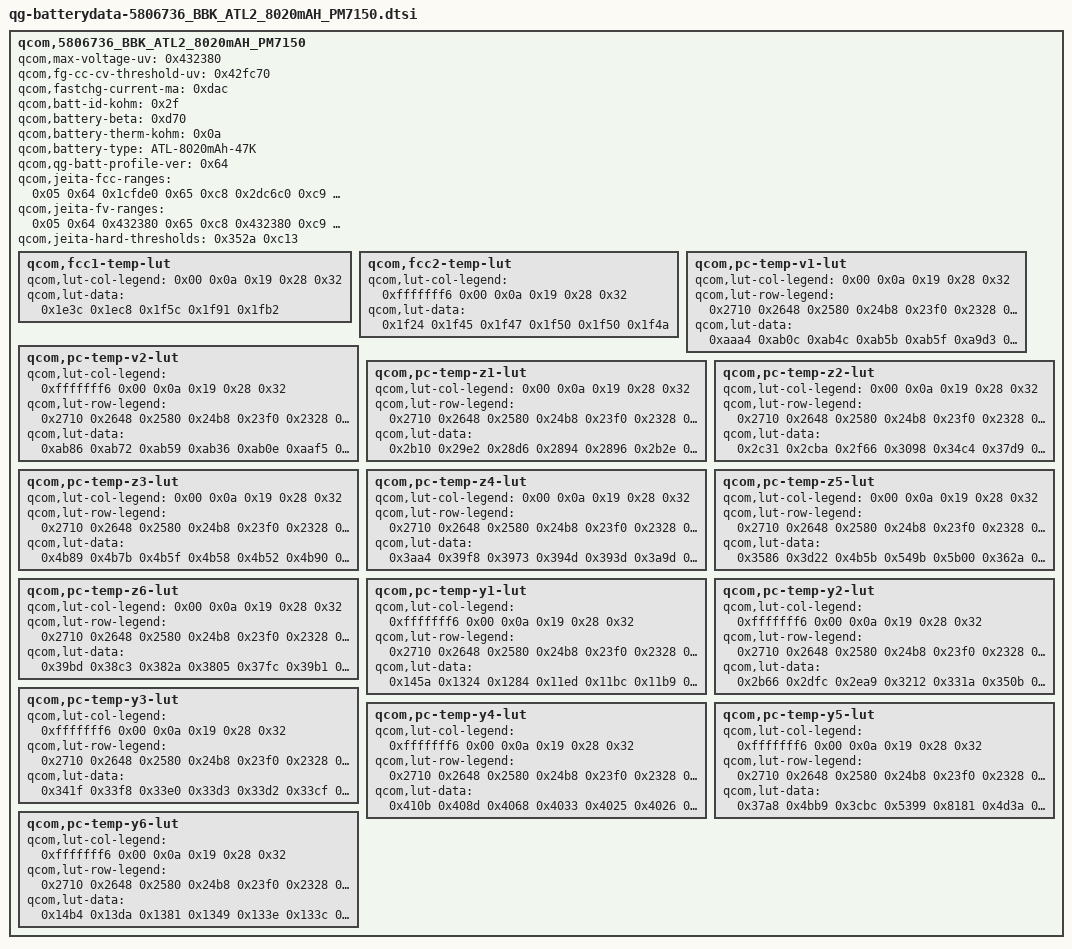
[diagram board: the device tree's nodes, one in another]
 /*
 * Copyright (c) 2026 XiKoTaSu <3329989998@qq.com>
 */


		qcom,5806736_BBK_ATL2_8020mAH_PM7150 {
				qcom,max-voltage-uv = <0x432380>;
				qcom,fg-cc-cv-threshold-uv = <0x42fc70>;
				qcom,fastchg-current-ma = <0xdac>;
				qcom,batt-id-kohm = <0x2f>;
				qcom,battery-beta = <0xd70>;
				qcom,battery-therm-kohm = <0x0a>;
				qcom,battery-type = "ATL-8020mAh-47K";
				qcom,qg-batt-profile-ver = <0x64>;
				qcom,jeita-fcc-ranges = <0x05 0x64 0x1cfde0 0x65 0xc8 0x2dc6c0 0xc9 0x1c2 0x3567e0 0x1c3 0x221 0x2625a0>;
				qcom,jeita-fv-ranges = <0x05 0x64 0x432380 0x65 0xc8 0x432380 0xc9 0x1c2 0x432380 0x1c3 0x221 0x3e8fa0>;
				qcom,jeita-hard-thresholds = <0x352a 0xc13>;

				qcom,fcc1-temp-lut {
					qcom,lut-col-legend = <0x00 0x0a 0x19 0x28 0x32>;
					qcom,lut-data = <0x1e3c 0x1ec8 0x1f5c 0x1f91 0x1fb2>;
				};

				qcom,fcc2-temp-lut {
					qcom,lut-col-legend = <0xfffffff6 0x00 0x0a 0x19 0x28 0x32>;
					qcom,lut-data = <0x1f24 0x1f45 0x1f47 0x1f50 0x1f50 0x1f4a>;
				};

				qcom,pc-temp-v1-lut {
					qcom,lut-col-legend = <0x00 0x0a 0x19 0x28 0x32>;
					qcom,lut-row-legend = <0x2710 0x2648 0x2580 0x24b8 0x23f0 0x2328 0x2260 0x2198 0x20d0 0x2008 0x1f40 0x1e78 0x1db0 0x1ce8 0x1c20 0x1b58 0x1a90 0x19c8 0x1900 0x1838 0x1770 0x16a8 0x15e0 0x1518 0x1450 0x1388 0x12c0 0x11f8 0x1130 0x1068 0xfa0 0xed8 0xe10 0xd48 0xc80 0xbb8 0xaf0 0xa28 0x960 0x898 0x7d0 0x708 0x640 0x578 0x4b0 0x3e8 0x384 0x320 0x2bc 0x258 0x1f4 0x190 0x12c 0xc8 0x64 0x00>;
					qcom,lut-data = <0xaaa4 0xab0c 0xab4c 0xab5b 0xab5f 0xa9d3 0xaa2c 0xaa8f 0xaa9c 0xaaa7 0xa8d4 0xa942 0xa9af 0xa9c9 0xa9d7 0xa7c5 0xa84c 0xa8c6 0xa8e9 0xa8fa 0xa6cb 0xa753 0xa7cf 0xa7fa 0xa810 0xa5dc 0xa660 0xa6d6 0xa702 0xa71b 0xa4f8 0xa572 0xa5e3 0xa60e 0xa62a 0xa422 0xa488 0xa4f4 0xa51c 0xa53b 0xa353 0xa3a6 0xa408 0xa42e 0xa44e 0xa283 0xa2c9 0xa31e 0xa345 0xa363 0xa1b0 0xa1f1 0xa239 0xa260 0xa27b 0xa0e4 0xa11d 0xa15b 0xa17e 0xa199 0xa02c 0xa051 0xa082 0xa09f 0xa0ba 0x9f7e 0x9f96 0x9fb2 0x9fc8 0x9fe2 0x9eb0 0x9ed8 0x9eeb 0x9ef8 0x9f0e 0x9d9e 0x9df7 0x9e24 0x9e2f 0x9e40 0x9c91 0x9cf0 0x9d53 0x9d6b 0x9d7c 0x9be0 0x9c11 0x9c82 0x9cae 0x9cc1 0x9b61 0x9b7b 0x9bbe 0x9bef 0x9c03 0x9acf 0x9af4 0x9b09 0x9b2e 0x9b41 0x99ef 0x9a3b 0x9a4e 0x9a69 0x9a7a 0x98fe 0x993a 0x996f 0x998e 0x99a3 0x985f 0x9865 0x988a 0x98a5 0x98bc 0x97ef 0x97eb 0x97e1 0x97ec 0x97fd 0x9795 0x978b 0x9761 0x9761 0x976e 0x974e 0x972e 0x96f1 0x96e9 0x96f3 0x9713 0x96d2 0x9689 0x967a 0x967f 0x96d3 0x967c 0x962a 0x9616 0x9613 0x968a 0x962a 0x95d4 0x95ba 0x95b2 0x9644 0x95de 0x9587 0x9564 0x9557 0x9608 0x959d 0x9543 0x9518 0x9506 0x95d2 0x9566 0x9508 0x94d5 0x94be 0x95a0 0x9534 0x94d4 0x949b 0x947e 0x9572 0x9509 0x94a6 0x9464 0x9442 0x9547 0x94e3 0x947f 0x9433 0x940c 0x951d 0x94bb 0x9458 0x9401 0x93d5 0x94f8 0x9495 0x942e 0x93cd 0x9398 0x94ca 0x946a 0x9402 0x9395 0x9355 0x947d 0x9423 0x93c0 0x9350 0x9308 0x9411 0x93bb 0x935e 0x92f7 0x92ae 0x939b 0x9347 0x92ee 0x9290 0x9248 0x9313 0x92c7 0x9275 0x9216 0x91ce 0x9283 0x923b 0x91ef 0x918e 0x9147 0x91ea 0x919c 0x9155 0x90fe 0x90ba 0x917e 0x9135 0x90e7 0x9092 0x9052 0x9148 0x90fa 0x90ae 0x9059 0x901f 0x912c 0x90e4 0x909c 0x9049 0x900e 0x9103 0x90cf 0x908c 0x903b 0x8ffd 0x909d 0x9089 0x9062 0x9010 0x8fcb 0x8f69 0x8f97 0x8fa4 0x8f43 0x8ee1 0x8d3b 0x8d9e 0x8df3 0x8da8 0x8d43 0x8a60 0x8aea 0x8b8c 0x8b6b 0x8b09 0x870a 0x878c 0x8863 0x8869 0x880c 0x82f7 0x8369 0x8452 0x8465 0x8405 0x7d5b 0x7dba 0x7ead 0x7eb5 0x7e42 0x7530 0x7530 0x7530 0x7530 0x7530>;
				};

				qcom,pc-temp-v2-lut {
					qcom,lut-col-legend = <0xfffffff6 0x00 0x0a 0x19 0x28 0x32>;
					qcom,lut-row-legend = <0x2710 0x2648 0x2580 0x24b8 0x23f0 0x2328 0x2260 0x2198 0x20d0 0x2008 0x1f40 0x1e78 0x1db0 0x1ce8 0x1c20 0x1b58 0x1a90 0x19c8 0x1900 0x1838 0x1770 0x16a8 0x15e0 0x1518 0x1450 0x1388 0x12c0 0x11f8 0x1130 0x1068 0xfa0 0xed8 0xe10 0xd48 0xc80 0xbb8 0xaf0 0xa28 0x960 0x898 0x7d0 0x708 0x640 0x578 0x4b0 0x3e8 0x384 0x320 0x2bc 0x258 0x1f4 0x190 0x12c 0xc8 0x64 0x00>;
					qcom,lut-data = <0xab86 0xab72 0xab59 0xab36 0xab0e 0xaaf5 0xaa28 0xaa49 0xaa54 0xaa3f 0xaa1f 0xaa08 0xa8e2 0xa92c 0xa951 0xa947 0xa92e 0xa91a 0xa7b9 0xa81b 0xa851 0xa84e 0xa83b 0xa829 0xa6a9 0xa716 0xa754 0xa753 0xa743 0xa734 0xa5a8 0xa61a 0xa65b 0xa65a 0xa64c 0xa640 0xa4b0 0xa523 0xa565 0xa566 0xa55a 0xa54e 0xa3c3 0xa433 0xa474 0xa475 0xa46a 0xa45f 0xa2d7 0xa34b 0xa38a 0xa389 0xa37f 0xa374 0xa1e9 0xa26a 0xa2a6 0xa2a0 0xa297 0xa28d 0xa110 0xa191 0xa1c6 0xa1bc 0xa1b3 0xa1aa 0xa063 0xa0c7 0xa0ea 0xa0dc 0xa0d4 0xa0cb 0x9fc4 0xa002 0xa012 0xa000 0x9ff8 0x9fef 0x9ef1 0x9f2b 0x9f3e 0x9f2d 0x9f23 0x9f1c 0x9dcf 0x9e42 0x9e6f 0x9e62 0x9e54 0x9e4d 0x9ca5 0x9d52 0x9d99 0x9d99 0x9d8c 0x9d85 0x9b99 0x9c5c 0x9caf 0x9ccc 0x9cce 0x9cc7 0x9a9d 0x9b65 0x9bbe 0x9c00 0x9c14 0x9c0d 0x99bf 0x9a80 0x9adc 0x9b36 0x9b50 0x9b4a 0x98fb 0x99a9 0x9a05 0x9a6c 0x9a82 0x9a7b 0x9846 0x98e0 0x9938 0x999e 0x99ae 0x99a8 0x979a 0x9822 0x986d 0x98b9 0x98c8 0x98c5 0x96fa 0x9774 0x97ae 0x97d7 0x97e5 0x97e8 0x9667 0x96dc 0x9712 0x972e 0x973c 0x9740 0x95df 0x9659 0x968f 0x96aa 0x96b9 0x96bd 0x9568 0x95e3 0x961b 0x9636 0x9645 0x9648 0x9503 0x9578 0x95b1 0x95c9 0x95d7 0x95d8 0x94ab 0x9518 0x9551 0x9566 0x9572 0x9572 0x9465 0x94c3 0x94f7 0x950c 0x9516 0x9515 0x942b 0x9476 0x94a1 0x94bb 0x94c1 0x94be 0x93fa 0x9438 0x9456 0x9472 0x9475 0x9470 0x93d0 0x940c 0x9416 0x942d 0x9433 0x942c 0x93aa 0x93e8 0x93e0 0x93ee 0x93f6 0x93ed 0x9384 0x93c9 0x93b7 0x93b4 0x93b0 0x939f 0x9361 0x93b0 0x939c 0x9380 0x935f 0x933f 0x9339 0x9395 0x937d 0x934a 0x930d 0x92dd 0x930b 0x9375 0x9354 0x930e 0x92be 0x9281 0x92d0 0x934f 0x9322 0x92d0 0x926f 0x9229 0x9280 0x9318 0x92e2 0x928d 0x9225 0x91db 0x9207 0x92c0 0x9292 0x9247 0x91e3 0x919a 0x916a 0x9253 0x9232 0x91f7 0x9198 0x9150 0x90a8 0x91d4 0x91bd 0x918d 0x912e 0x90e6 0x8fb1 0x913c 0x9134 0x9110 0x90b2 0x906b 0x8e65 0x9082 0x9091 0x906f 0x901f 0x8fdf 0x8d15 0x8fd9 0x9025 0x901a 0x8fd8 0x8f9e 0x8c1d 0x8f33 0x8fcf 0x8fed 0x8fbb 0x8f80 0x8bc9 0x8eda 0x8f9f 0x8fd1 0x8fa4 0x8f68 0x8b6e 0x8e60 0x8f48 0x8fa5 0x8f7a 0x8f45 0x8b00 0x8da6 0x8eb7 0x8f4a 0x8f32 0x8ef6 0x8a61 0x8c81 0x8d96 0x8e70 0x8e54 0x8de8 0x8918 0x8a86 0x8b9b 0x8cb9 0x8c90 0x8c17 0x870d 0x87e2 0x88ee 0x8a36 0x8a29 0x89a4 0x846e 0x84d2 0x85ba 0x8703 0x86fa 0x8669 0x8104 0x80f3 0x81b3 0x82fa 0x82d3 0x8224 0x7bf6 0x7b5b 0x7c0a 0x7d4f 0x7ce5 0x7be5 0x70f8 0x6e47 0x6f11 0x70eb 0x706f 0x6f0b>;
				};

				qcom,pc-temp-z1-lut {
					qcom,lut-col-legend = <0x00 0x0a 0x19 0x28 0x32>;
					qcom,lut-row-legend = <0x2710 0x2648 0x2580 0x24b8 0x23f0 0x2328 0x2260 0x2198 0x20d0 0x2008 0x1f40 0x1e78 0x1db0 0x1ce8 0x1c20 0x1b58 0x1a90 0x19c8 0x1900 0x1838 0x1770 0x16a8 0x15e0 0x1518 0x1450 0x1388 0x12c0 0x11f8 0x1130 0x1068 0xfa0 0xed8 0xe10 0xd48 0xc80 0xbb8 0xaf0 0xa28 0x960 0x898 0x7d0 0x708 0x640 0x578 0x4b0 0x3e8 0x384 0x320 0x2bc 0x258 0x1f4 0x190 0x12c 0xc8 0x64 0x00>;
					qcom,lut-data = <0x2b10 0x29e2 0x28d6 0x2894 0x2896 0x2b2e 0x29ee 0x28ed 0x28a5 0x28a7 0x2b28 0x29f0 0x28ee 0x28a9 0x28ab 0x2b1f 0x29ec 0x28ed 0x28aa 0x28ad 0x2b1d 0x29e7 0x28eb 0x28ab 0x28b0 0x2b1d 0x29e4 0x28e9 0x28ac 0x28b2 0x2b1c 0x29e1 0x28e7 0x28ad 0x28b3 0x2b12 0x29df 0x28e6 0x28ae 0x28b4 0x2b01 0x29dd 0x28e4 0x28ae 0x28b5 0x2af9 0x29da 0x28e3 0x28ad 0x28b4 0x2af4 0x29d7 0x28e1 0x28ac 0x28b2 0x2af1 0x29d2 0x28e1 0x28ab 0x28b2 0x2aed 0x29ce 0x28e1 0x28ab 0x28b3 0x2aed 0x29cb 0x28e0 0x28ab 0x28b3 0x2aed 0x29c8 0x28de 0x28ab 0x28b4 0x2ae7 0x29c5 0x28dc 0x28ab 0x28b4 0x2ade 0x29c1 0x28dc 0x28ab 0x28b4 0x2ada 0x29bf 0x28dc 0x28ab 0x28b4 0x2ad4 0x29c0 0x28dc 0x28ac 0x28b5 0x2ad2 0x29c2 0x28de 0x28ad 0x28b5 0x2ada 0x29c5 0x28e0 0x28ad 0x28b5 0x2ae4 0x29c9 0x28e2 0x28ae 0x28b6 0x2ae8 0x29cd 0x28e3 0x28ae 0x28b8 0x2aec 0x29d1 0x28e5 0x28af 0x28b9 0x2aef 0x29d5 0x28e7 0x28b0 0x28ba 0x2aea 0x29d5 0x28ea 0x28b1 0x28ba 0x2ae2 0x29d2 0x28eb 0x28b2 0x28bb 0x2ae1 0x29cf 0x28ec 0x28b3 0x28bb 0x2aeb 0x29cf 0x28ed 0x28b5 0x28bc 0x2af5 0x29d0 0x28ee 0x28b6 0x28bd 0x2af4 0x29d0 0x28f0 0x28b7 0x28be 0x2aec 0x29d2 0x28f2 0x28b8 0x28bf 0x2ae9 0x29d5 0x28f3 0x28b8 0x28bf 0x2aec 0x29d9 0x28f5 0x28b9 0x28c0 0x2af0 0x29e0 0x28f7 0x28ba 0x28c0 0x2af4 0x29e3 0x28f8 0x28bb 0x28c0 0x2afa 0x29e4 0x28fa 0x28bb 0x28c1 0x2aff 0x29e4 0x28fb 0x28bc 0x28c3 0x2afe 0x29e6 0x28fd 0x28bd 0x28c4 0x2afc 0x29e8 0x28fe 0x28be 0x28c4 0x2afc 0x29ea 0x28ff 0x28bf 0x28c4 0x2afe 0x29ef 0x2900 0x28bf 0x28c5 0x2b03 0x29f2 0x2901 0x28c0 0x28c5 0x2b0b 0x29ee 0x2903 0x28c0 0x28c6 0x2b1f 0x29ed 0x2905 0x28c1 0x28c7 0x2b0d 0x29f3 0x2904 0x28c2 0x28c6 0x2b06 0x29f1 0x2905 0x28c1 0x28c7 0x2b0a 0x29f3 0x2906 0x28c1 0x28c7 0x2b12 0x29f8 0x2907 0x28c2 0x28c7 0x2b17 0x29f8 0x2906 0x28c3 0x28c8 0x2b12 0x29f8 0x290f 0x28c6 0x28cb 0x2b17 0x2a0e 0x291a 0x28cc 0x28cf 0x2b1d 0x2a21 0x292d 0x28d7 0x28d7 0x2b28 0x2a2d 0x2940 0x28e6 0x28e3 0x2b28 0x2a2d 0x2940 0x28e6 0x28e3 0x2b28 0x2a2d 0x2940 0x28e6 0x28e3>;
				};

				qcom,pc-temp-z2-lut {
					qcom,lut-col-legend = <0x00 0x0a 0x19 0x28 0x32>;
					qcom,lut-row-legend = <0x2710 0x2648 0x2580 0x24b8 0x23f0 0x2328 0x2260 0x2198 0x20d0 0x2008 0x1f40 0x1e78 0x1db0 0x1ce8 0x1c20 0x1b58 0x1a90 0x19c8 0x1900 0x1838 0x1770 0x16a8 0x15e0 0x1518 0x1450 0x1388 0x12c0 0x11f8 0x1130 0x1068 0xfa0 0xed8 0xe10 0xd48 0xc80 0xbb8 0xaf0 0xa28 0x960 0x898 0x7d0 0x708 0x640 0x578 0x4b0 0x3e8 0x384 0x320 0x2bc 0x258 0x1f4 0x190 0x12c 0xc8 0x64 0x00>;
					qcom,lut-data = <0x2c31 0x2cba 0x2f66 0x3098 0x34c4 0x37d9 0x2d7e 0x2f88 0x30f3 0x3175 0x32ee 0x2dbe 0x3016 0x317e 0x3189 0x2d16 0x2dc3 0x3068 0x31c7 0x319d 0x2c44 0x2dc6 0x30a5 0x31da 0x31ad 0x2c47 0x2dc7 0x30c2 0x31eb 0x31b8 0x2c4c 0x2dc1 0x30b9 0x320b 0x31a0 0x2cf3 0x2dc6 0x30a9 0x323b 0x3117 0x2ddd 0x2de7 0x30aa 0x324c 0x30bf 0x2de2 0x2e0e 0x30c9 0x31c9 0x30dd 0x2d09 0x2e23 0x30e2 0x3121 0x3110 0x2c6e 0x2e30 0x30e6 0x30ed 0x313a 0x2c84 0x2e41 0x30e6 0x30d5 0x31c7 0x2cb0 0x2e65 0x30e4 0x30d5 0x3217 0x2cdd 0x2e86 0x30db 0x3104 0x31f4 0x2d16 0x2e89 0x30ce 0x3143 0x31c8 0x2d40 0x2e85 0x30b8 0x3175 0x31cd 0x2d42 0x2e81 0x309d 0x31a7 0x31e0 0x2d37 0x2e7f 0x30a1 0x31b6 0x31f1 0x2d2e 0x2e7f 0x30e0 0x3195 0x31fe 0x2d2a 0x306f 0x310e 0x3174 0x320a 0x2d26 0x38f4 0x310a 0x320d 0x3203 0x2d29 0x3e38 0x3104 0x33a3 0x31cf 0x2d35 0x38e6 0x3111 0x3427 0x31b4 0x2d44 0x30ac 0x316c 0x3308 0x3116 0x2d53 0x2eed 0x31ad 0x3197 0x3047 0x2d66 0x2ef0 0x3126 0x30a4 0x2fe4 0x2d79 0x2ef0 0x303e 0x2fd6 0x2f5f 0x2d8e 0x2ee0 0x3005 0x2f8f 0x2f22 0x2d9d 0x2ec3 0x3005 0x2f81 0x2f1c 0x2d9a 0x2ebc 0x300d 0x2f82 0x2f25 0x2d8e 0x2ed1 0x302c 0x2f95 0x2f43 0x2d88 0x2ee9 0x305d 0x2fbd 0x2f85 0x2d92 0x2ef3 0x307f 0x2ffd 0x2fda 0x2da3 0x2efd 0x309d 0x3090 0x3067 0x2db2 0x2f06 0x30ba 0x312d 0x30e5 0x2dc2 0x2f0d 0x30d5 0x31aa 0x3122 0x2dcc 0x2f16 0x30f3 0x3218 0x314d 0x2dd0 0x2f2e 0x312e 0x3226 0x3159 0x2dd3 0x2f5a 0x31af 0x31cc 0x3155 0x2dd0 0x2f6b 0x31fd 0x315b 0x314a 0x2daf 0x2f43 0x31bd 0x30e7 0x30ff 0x2d99 0x2f2a 0x3170 0x3092 0x307d 0x2d96 0x2f31 0x316d 0x30aa 0x3023 0x2e4d 0x2f82 0x317c 0x30df 0x2fd8 0x2e5b 0x2f94 0x314c 0x3108 0x30b2 0x2e46 0x2f68 0x316a 0x30ef 0x3090 0x2e3a 0x2f5d 0x30fe 0x31f8 0x3121 0x2e5b 0x2f70 0x3138 0x3286 0x3125 0x2e1b 0x2fa7 0x318a 0x2f8e 0x2ea5 0x2d35 0x2ee5 0x3067 0x2e84 0x2de2 0x2b5d 0x2cb2 0x2f9f 0x2e31 0x2d74 0x28e3 0x2b8b 0x2ef3 0x2d8c 0x2d1f 0x264a 0x29fd 0x2e53 0x2d5a 0x2d2e 0x264a 0x29fd 0x2e53 0x2d5a 0x2d2e 0x264a 0x29fd 0x2e53 0x2d5a 0x2d2e>;
				};

				qcom,pc-temp-z3-lut {
					qcom,lut-col-legend = <0x00 0x0a 0x19 0x28 0x32>;
					qcom,lut-row-legend = <0x2710 0x2648 0x2580 0x24b8 0x23f0 0x2328 0x2260 0x2198 0x20d0 0x2008 0x1f40 0x1e78 0x1db0 0x1ce8 0x1c20 0x1b58 0x1a90 0x19c8 0x1900 0x1838 0x1770 0x16a8 0x15e0 0x1518 0x1450 0x1388 0x12c0 0x11f8 0x1130 0x1068 0xfa0 0xed8 0xe10 0xd48 0xc80 0xbb8 0xaf0 0xa28 0x960 0x898 0x7d0 0x708 0x640 0x578 0x4b0 0x3e8 0x384 0x320 0x2bc 0x258 0x1f4 0x190 0x12c 0xc8 0x64 0x00>;
					qcom,lut-data = <0x4b89 0x4b7b 0x4b5f 0x4b58 0x4b52 0x4b90 0x4ba2 0x4b71 0x4b5a 0x4b55 0x4bc6 0x4bb4 0x4b79 0x4b60 0x4b5a 0x4c03 0x4bbb 0x4b7e 0x4b65 0x4b5f 0x4c10 0x4bbf 0x4b83 0x4b6a 0x4b63 0x4c13 0x4bbf 0x4b85 0x4b6c 0x4b65 0x4c14 0x4bbf 0x4b83 0x4b6c 0x4b65 0x4c16 0x4bbe 0x4b7e 0x4b6b 0x4b62 0x4c17 0x4bbb 0x4b7c 0x4b69 0x4b60 0x4c16 0x4bb8 0x4b7a 0x4b66 0x4b5e 0x4c10 0x4bb7 0x4b79 0x4b62 0x4b5d 0x4c0a 0x4bb6 0x4b78 0x4b61 0x4b5c 0x4c04 0x4bb5 0x4b78 0x4b60 0x4b59 0x4bfd 0x4bb2 0x4b76 0x4b5f 0x4b58 0x4bfb 0x4bb0 0x4b72 0x4b5c 0x4b57 0x4bfe 0x4baf 0x4b6f 0x4b5a 0x4b56 0x4c01 0x4bb0 0x4b6f 0x4b59 0x4b55 0x4c01 0x4bb0 0x4b70 0x4b59 0x4b54 0x4bfc 0x4baf 0x4b71 0x4b59 0x4b54 0x4bf9 0x4bae 0x4b75 0x4b5a 0x4b54 0x4c00 0x4bad 0x4b77 0x4b5b 0x4b55 0x4c09 0x4ba9 0x4b73 0x4b60 0x4b58 0x4c0a 0x4ba6 0x4b6c 0x4b6a 0x4b62 0x4c05 0x4ba7 0x4b6d 0x4b70 0x4b68 0x4c00 0x4ba9 0x4b7f 0x4b73 0x4b68 0x4bff 0x4bae 0x4b8c 0x4b75 0x4b67 0x4bfe 0x4bb8 0x4b8d 0x4b73 0x4b66 0x4bfe 0x4bc0 0x4b8d 0x4b6e 0x4b64 0x4c02 0x4bc1 0x4b8c 0x4b6a 0x4b63 0x4c05 0x4bc2 0x4b8a 0x4b69 0x4b61 0x4c05 0x4bc2 0x4b88 0x4b68 0x4b60 0x4c03 0x4bbf 0x4b85 0x4b66 0x4b5f 0x4c02 0x4bbc 0x4b82 0x4b64 0x4b5d 0x4c01 0x4bba 0x4b80 0x4b63 0x4b5c 0x4c01 0x4bb8 0x4b7d 0x4b63 0x4b5a 0x4c00 0x4bb7 0x4b7b 0x4b62 0x4b59 0x4bfe 0x4bb6 0x4b7a 0x4b63 0x4b59 0x4bfb 0x4bb5 0x4b7a 0x4b63 0x4b59 0x4bf8 0x4bb3 0x4b79 0x4b63 0x4b59 0x4bf3 0x4baf 0x4b78 0x4b61 0x4b5b 0x4bf2 0x4bac 0x4b77 0x4b5f 0x4b5c 0x4bf1 0x4baa 0x4b74 0x4b60 0x4b5c 0x4bf1 0x4ba8 0x4b71 0x4b61 0x4b5d 0x4beb 0x4ba7 0x4b71 0x4b61 0x4b5e 0x4bd5 0x4b9c 0x4b6e 0x4b5e 0x4b5e 0x4bca 0x4b96 0x4b69 0x4b5b 0x4b53 0x4bc9 0x4b96 0x4b6a 0x4b5b 0x4b53 0x4bc4 0x4b92 0x4b65 0x4b52 0x4b4f 0x4bbc 0x4b92 0x4b62 0x4b51 0x4b52 0x4bbd 0x4b91 0x4b6c 0x4b64 0x4b5c 0x4bc2 0x4b95 0x4b76 0x4b69 0x4b5f 0x4bcc 0x4b8e 0x4b7c 0x4b6a 0x4b63 0x4bbe 0x4b8e 0x4b7e 0x4b6a 0x4b65 0x4ba9 0x4b7f 0x4b77 0x4b6b 0x4b65 0x4ba9 0x4b7f 0x4b77 0x4b6b 0x4b65 0x4ba9 0x4b7f 0x4b77 0x4b6b 0x4b65>;
				};

				qcom,pc-temp-z4-lut {
					qcom,lut-col-legend = <0x00 0x0a 0x19 0x28 0x32>;
					qcom,lut-row-legend = <0x2710 0x2648 0x2580 0x24b8 0x23f0 0x2328 0x2260 0x2198 0x20d0 0x2008 0x1f40 0x1e78 0x1db0 0x1ce8 0x1c20 0x1b58 0x1a90 0x19c8 0x1900 0x1838 0x1770 0x16a8 0x15e0 0x1518 0x1450 0x1388 0x12c0 0x11f8 0x1130 0x1068 0xfa0 0xed8 0xe10 0xd48 0xc80 0xbb8 0xaf0 0xa28 0x960 0x898 0x7d0 0x708 0x640 0x578 0x4b0 0x3e8 0x384 0x320 0x2bc 0x258 0x1f4 0x190 0x12c 0xc8 0x64 0x00>;
					qcom,lut-data = <0x3aa4 0x39f8 0x3973 0x394d 0x393d 0x3a9d 0x3a07 0x399b 0x396c 0x395b 0x3a7b 0x3a07 0x3997 0x3969 0x3958 0x3a4a 0x39e8 0x3991 0x3964 0x3953 0x3a21 0x39c1 0x397e 0x395a 0x394b 0x39fa 0x39a6 0x396a 0x394d 0x3941 0x39d5 0x398e 0x395d 0x3944 0x393a 0x39ae 0x397b 0x3953 0x393c 0x3935 0x398d 0x396a 0x394b 0x3937 0x3931 0x3982 0x395e 0x3945 0x3935 0x392e 0x397d 0x395b 0x3941 0x3934 0x392c 0x397a 0x3959 0x393e 0x3931 0x3929 0x3972 0x3957 0x393c 0x392d 0x3927 0x3967 0x3952 0x3939 0x392a 0x3924 0x3965 0x394e 0x3936 0x3927 0x3921 0x397a 0x394f 0x3933 0x3924 0x391e 0x3991 0x3955 0x392f 0x3921 0x391b 0x398e 0x3959 0x392b 0x391d 0x3918 0x397b 0x3954 0x392c 0x391c 0x3917 0x3972 0x394e 0x3932 0x3924 0x391d 0x3993 0x3959 0x393c 0x3930 0x3928 0x39c7 0x3996 0x395c 0x393d 0x3931 0x39d7 0x39bf 0x3989 0x394c 0x393c 0x39db 0x39bb 0x398f 0x3950 0x3940 0x39dd 0x39b2 0x3975 0x3946 0x393b 0x39d6 0x39a6 0x395d 0x393b 0x3934 0x39c5 0x3992 0x3954 0x3938 0x3930 0x39b9 0x3982 0x394e 0x3936 0x392c 0x39b1 0x397c 0x3949 0x3934 0x3929 0x39ab 0x3978 0x3946 0x3930 0x3926 0x39aa 0x3977 0x3944 0x392d 0x3924 0x39aa 0x3977 0x3942 0x392b 0x3922 0x39aa 0x3978 0x3942 0x3929 0x3920 0x39ac 0x3979 0x3942 0x3929 0x391f 0x39af 0x397b 0x3942 0x392b 0x3922 0x39b1 0x397c 0x3944 0x392e 0x3925 0x39b2 0x397e 0x3945 0x3930 0x3929 0x39b2 0x3980 0x3947 0x3932 0x392d 0x39b3 0x3982 0x394a 0x3933 0x392e 0x39b3 0x3985 0x394d 0x3934 0x392a 0x39b2 0x3987 0x394f 0x3934 0x3926 0x39ab 0x3984 0x3950 0x3931 0x3924 0x39a1 0x397f 0x3950 0x392e 0x3922 0x3994 0x3978 0x3951 0x392f 0x3921 0x396a 0x395e 0x394b 0x392e 0x391e 0x395a 0x394a 0x393b 0x3924 0x391c 0x3953 0x3945 0x3931 0x391c 0x3915 0x394a 0x3940 0x392f 0x391d 0x3911 0x3945 0x393a 0x392f 0x391d 0x390e 0x394b 0x3940 0x3930 0x3917 0x3911 0x395d 0x3945 0x392d 0x3917 0x3913 0x396e 0x3954 0x392b 0x391c 0x3916 0x3993 0x395b 0x392a 0x3920 0x3918 0x39b7 0x396c 0x3930 0x391f 0x3919 0x39b7 0x396c 0x3930 0x391f 0x3919 0x39b7 0x396c 0x3930 0x391f 0x3919>;
				};

				qcom,pc-temp-z5-lut {
					qcom,lut-col-legend = <0x00 0x0a 0x19 0x28 0x32>;
					qcom,lut-row-legend = <0x2710 0x2648 0x2580 0x24b8 0x23f0 0x2328 0x2260 0x2198 0x20d0 0x2008 0x1f40 0x1e78 0x1db0 0x1ce8 0x1c20 0x1b58 0x1a90 0x19c8 0x1900 0x1838 0x1770 0x16a8 0x15e0 0x1518 0x1450 0x1388 0x12c0 0x11f8 0x1130 0x1068 0xfa0 0xed8 0xe10 0xd48 0xc80 0xbb8 0xaf0 0xa28 0x960 0x898 0x7d0 0x708 0x640 0x578 0x4b0 0x3e8 0x384 0x320 0x2bc 0x258 0x1f4 0x190 0x12c 0xc8 0x64 0x00>;
					qcom,lut-data = <0x3586 0x3d22 0x4b5b 0x549b 0x5b00 0x362a 0x4e00 0x552c 0x5be6 0x63f5 0x4304 0x585a 0x5c90 0x6306 0x6c59 0x54a7 0x5e0b 0x632e 0x69a2 0x73f2 0x5ea7 0x62b6 0x69d7 0x6fb3 0x7d38 0x6551 0x67b7 0x6da4 0x75b1 0x8587 0x6bf5 0x6c9a 0x6e11 0x7bb0 0x8696 0x73ba 0x7272 0x6e4b 0x81e9 0x8302 0x7bd0 0x7a98 0x6f44 0x8423 0x80ad 0x839b 0x82af 0x7334 0x7d6f 0x8122 0x8ba5 0x880f 0x772e 0x7595 0x81bb 0x9220 0x8c2a 0x799c 0x75f5 0x80dc 0x9879 0x917b 0x7b7a 0x79ab 0x7cd1 0xa0da 0x9c39 0x7bf1 0x7b39 0x7a65 0xa4db 0xa61a 0x7b15 0x7895 0x7d36 0xa5a6 0xa4e0 0x7a98 0x75b0 0x82ab 0xa665 0x9b26 0x7d2d 0x79be 0x882e 0xa74c 0x95af 0x8382 0x861a 0x8f1e 0xa867 0xa102 0x8f08 0x8b0d 0x9216 0xac5e 0xb11f 0xab07 0x8a13 0x8c73 0xd20b 0xb0b6 0xbd47 0x880f 0x82cc 0xffff 0xa04b 0x9dac 0x7f6f 0x7a01 0xffff 0x9226 0x671c 0x6d6f 0x70af 0xe54d 0x85ef 0x5c97 0x67c9 0x6c22 0xc181 0x774f 0x68f4 0x7393 0x6f33 0xb210 0x754d 0x7672 0x7ee4 0x747f 0xa729 0x81eb 0x7fac 0x7e25 0x77ec 0xa565 0x9282 0x8908 0x7b26 0x7cfe 0xb171 0xa4cd 0x92f7 0x7ad3 0x832f 0xbe6d 0xb7b8 0x9eaf 0x836c 0x8b8e 0xc1c5 0xbcc6 0xa89d 0x8f09 0x9570 0xc3af 0xbc7f 0xb030 0x987e 0xa1d0 0xc48a 0xbbec 0xb5dd 0xa1ce 0xb001 0xc522 0xba71 0xb644 0xa9aa 0xb426 0xc576 0xb724 0xb201 0xb184 0xafed 0xc443 0xb2ff 0xabe4 0xb5f4 0xa90b 0xc02f 0xad11 0xa3af 0xb143 0x9d4c 0xbb22 0xa59a 0x991b 0xa4a3 0x8d3a 0xb465 0x9c73 0x8f13 0x9675 0x88de 0xad08 0x912c 0x8549 0x8240 0x8a55 0xaacd 0x8860 0x7b23 0x7485 0x8b8d 0xaa97 0x816c 0x6eb7 0x7293 0x8984 0xaa54 0x7eb6 0x6502 0x713f 0x84ce 0xa944 0x801e 0x60f6 0x68c5 0x8006 0xbe0a 0x8528 0x6070 0x6167 0x7968 0xb276 0x8b91 0x616b 0x616b 0x5c19 0xafd9 0x8dc9 0x6b55 0x69c1 0x6476 0xa93c 0x86cc 0x63f5 0x580b 0x653d 0x986e 0x907e 0x61a4 0x595f 0x7475 0x980b 0x8856 0x6a53 0x8157 0x8514 0x7ab7 0x7a26 0x7ad1 0x931d 0x8e75 0x6a38 0x637c 0x8b70 0x8ff7 0xa09f 0x53a9 0x5b70 0x8b39 0x8631 0x9828 0x3c13 0x4890 0x6f03 0x85b9 0x9507 0x3c13 0x4890 0x6f03 0x85b9 0x9507 0x3c13 0x4890 0x6f03 0x85b9 0x9507>;
				};

				qcom,pc-temp-z6-lut {
					qcom,lut-col-legend = <0x00 0x0a 0x19 0x28 0x32>;
					qcom,lut-row-legend = <0x2710 0x2648 0x2580 0x24b8 0x23f0 0x2328 0x2260 0x2198 0x20d0 0x2008 0x1f40 0x1e78 0x1db0 0x1ce8 0x1c20 0x1b58 0x1a90 0x19c8 0x1900 0x1838 0x1770 0x16a8 0x15e0 0x1518 0x1450 0x1388 0x12c0 0x11f8 0x1130 0x1068 0xfa0 0xed8 0xe10 0xd48 0xc80 0xbb8 0xaf0 0xa28 0x960 0x898 0x7d0 0x708 0x640 0x578 0x4b0 0x3e8 0x384 0x320 0x2bc 0x258 0x1f4 0x190 0x12c 0xc8 0x64 0x00>;
					qcom,lut-data = <0x39bd 0x38c3 0x382a 0x3805 0x37fc 0x39b1 0x38da 0x3845 0x3817 0x380d 0x39ad 0x38de 0x3848 0x381a 0x3810 0x39a8 0x38d1 0x3847 0x381b 0x3811 0x399d 0x38bf 0x3841 0x3819 0x3810 0x3984 0x38b1 0x383a 0x3815 0x380d 0x396a 0x38a3 0x3833 0x3811 0x380b 0x3954 0x3897 0x382b 0x380e 0x3807 0x3940 0x388d 0x3826 0x380a 0x3803 0x3933 0x3885 0x3823 0x3807 0x3801 0x392a 0x3882 0x3820 0x3804 0x3800 0x3922 0x3880 0x381e 0x3802 0x37fe 0x3918 0x387e 0x381c 0x3800 0x37fb 0x390e 0x3879 0x381a 0x37fe 0x37f9 0x390b 0x3874 0x3816 0x37fb 0x37f7 0x3912 0x3874 0x3813 0x37f9 0x37f6 0x391b 0x3876 0x3811 0x37f7 0x37f4 0x3919 0x3877 0x3810 0x37f5 0x37f2 0x390f 0x3875 0x3810 0x37f5 0x37f1 0x390a 0x3873 0x3815 0x37f8 0x37f4 0x391d 0x3878 0x381c 0x37fe 0x37f9 0x393a 0x3892 0x3828 0x3808 0x3800 0x3940 0x38a4 0x3838 0x3814 0x380b 0x3940 0x38a3 0x383b 0x3818 0x380f 0x3940 0x389f 0x3839 0x3816 0x380d 0x393d 0x389d 0x3837 0x3813 0x380a 0x3935 0x389a 0x3835 0x3810 0x3808 0x3933 0x3898 0x3832 0x380d 0x3806 0x3932 0x3896 0x382f 0x380a 0x3804 0x3932 0x3895 0x382d 0x3808 0x3802 0x3932 0x3895 0x382b 0x3807 0x3800 0x3931 0x3894 0x3829 0x3805 0x37fe 0x3931 0x3894 0x3828 0x3803 0x37fc 0x3933 0x3894 0x3827 0x3802 0x37fc 0x3935 0x3894 0x3826 0x3803 0x37fc 0x3936 0x3894 0x3826 0x3803 0x37fc 0x3937 0x3895 0x3826 0x3805 0x37fe 0x3938 0x3897 0x3827 0x3806 0x3800 0x3938 0x3898 0x3828 0x3806 0x3800 0x3938 0x3898 0x3829 0x3806 0x3800 0x3938 0x3898 0x382a 0x3805 0x37ff 0x3937 0x3897 0x3829 0x3804 0x37fe 0x3936 0x3895 0x3828 0x3804 0x37fd 0x3931 0x3892 0x3829 0x3804 0x37fe 0x391b 0x3883 0x3825 0x3803 0x37fd 0x3910 0x3879 0x381b 0x37fd 0x37f7 0x390c 0x3877 0x3817 0x37f9 0x37f3 0x3908 0x3872 0x3814 0x37f5 0x37f0 0x3905 0x3871 0x3812 0x37f5 0x37f0 0x390d 0x3876 0x3819 0x37fc 0x37f7 0x391f 0x3880 0x381f 0x3800 0x37fb 0x3936 0x388e 0x3825 0x3804 0x37ff 0x394d 0x389f 0x382c 0x3808 0x3803 0x3965 0x38af 0x3832 0x380c 0x3806 0x3965 0x38af 0x3832 0x380c 0x3806 0x3965 0x38af 0x3832 0x380c 0x3806>;
				};

				qcom,pc-temp-y1-lut {
					qcom,lut-col-legend = <0xfffffff6 0x00 0x0a 0x19 0x28 0x32>;
					qcom,lut-row-legend = <0x2710 0x2648 0x2580 0x24b8 0x23f0 0x2328 0x2260 0x2198 0x20d0 0x2008 0x1f40 0x1e78 0x1db0 0x1ce8 0x1c20 0x1b58 0x1a90 0x19c8 0x1900 0x1838 0x1770 0x16a8 0x15e0 0x1518 0x1450 0x1388 0x12c0 0x11f8 0x1130 0x1068 0xfa0 0xed8 0xe10 0xd48 0xc80 0xbb8 0xaf0 0xa28 0x960 0x898 0x7d0 0x708 0x640 0x578 0x4b0 0x3e8 0x384 0x320 0x2bc 0x258 0x1f4 0x190 0x12c 0xc8 0x64 0x00>;
					qcom,lut-data = <0x145a 0x1324 0x1284 0x11ed 0x11bc 0x11b9 0x143d 0x131f 0x1281 0x11ea 0x11bc 0x11bb 0x142b 0x131c 0x127e 0x11e7 0x11bc 0x11bc 0x1422 0x1319 0x127a 0x11e4 0x11bc 0x11bd 0x141e 0x1318 0x1277 0x11e2 0x11bb 0x11bd 0x141d 0x1317 0x1275 0x11e0 0x11bb 0x11bd 0x1427 0x1318 0x1275 0x11de 0x11bb 0x11bd 0x1436 0x131a 0x1275 0x11dc 0x11ba 0x11bc 0x1437 0x1319 0x1273 0x11db 0x11b9 0x11bb 0x1428 0x1313 0x126e 0x11da 0x11b8 0x11ba 0x141c 0x130f 0x1269 0x11d9 0x11b7 0x11ba 0x141e 0x130e 0x1268 0x11d8 0x11b7 0x11ba 0x1424 0x130d 0x1268 0x11d7 0x11b8 0x11ba 0x1425 0x130c 0x1266 0x11d7 0x11b8 0x11ba 0x1426 0x130a 0x1263 0x11d6 0x11b8 0x11bb 0x1428 0x1308 0x1261 0x11d5 0x11b8 0x11bb 0x1427 0x130a 0x1262 0x11d6 0x11b8 0x11bc 0x1424 0x130e 0x1263 0x11d7 0x11b8 0x11bc 0x1422 0x1310 0x1264 0x11d8 0x11b9 0x11bc 0x1421 0x1311 0x1262 0x11d7 0x11b9 0x11bc 0x1423 0x1311 0x1261 0x11d7 0x11ba 0x11bb 0x1421 0x130d 0x1261 0x11d8 0x11ba 0x11bb 0x141a 0x1309 0x1260 0x11d9 0x11ba 0x11bc 0x1419 0x130a 0x1261 0x11da 0x11ba 0x11bc 0x1423 0x1310 0x1263 0x11db 0x11ba 0x11bc 0x142d 0x1315 0x1264 0x11dc 0x11ba 0x11bd 0x1426 0x1313 0x1264 0x11dd 0x11bb 0x11bd 0x1416 0x130f 0x1265 0x11df 0x11bc 0x11bd 0x1410 0x130e 0x1265 0x11e0 0x11bc 0x11be 0x1412 0x1312 0x1266 0x11e0 0x11bd 0x11bf 0x1415 0x1315 0x1267 0x11e1 0x11bd 0x11c0 0x1415 0x1319 0x126a 0x11e2 0x11be 0x11c1 0x1416 0x131f 0x126c 0x11e4 0x11be 0x11c2 0x1416 0x1321 0x126e 0x11e6 0x11c0 0x11c3 0x1416 0x131f 0x1272 0x11e8 0x11c3 0x11c3 0x1415 0x131e 0x1274 0x11e9 0x11c4 0x11c3 0x1417 0x1321 0x1273 0x11e9 0x11c3 0x11c4 0x1421 0x1324 0x1271 0x11ea 0x11c2 0x11c4 0x1426 0x1325 0x1272 0x11eb 0x11c2 0x11c4 0x1420 0x1324 0x1278 0x11eb 0x11c3 0x11c4 0x1418 0x1324 0x127d 0x11ed 0x11c4 0x11c3 0x141c 0x1323 0x127c 0x11ef 0x11c4 0x11c4 0x1423 0x1322 0x127b 0x11f2 0x11c4 0x11c6 0x141e 0x132d 0x1282 0x11f3 0x11c4 0x11c7 0x141e 0x132b 0x1286 0x11f4 0x11c5 0x11c7 0x142b 0x1326 0x1281 0x11f6 0x11c8 0x11c7 0x1420 0x1326 0x128b 0x11f9 0x11c7 0x11cb 0x1419 0x1322 0x1289 0x11fb 0x11c8 0x11c8 0x1420 0x1329 0x1288 0x11fd 0x11c9 0x11ca 0x141e 0x1330 0x128a 0x1203 0x11ca 0x11c9 0x141b 0x1334 0x128d 0x1207 0x11ce 0x11cc 0x141b 0x133c 0x1296 0x120d 0x11d1 0x11cf 0x141d 0x1334 0x129a 0x1214 0x11d8 0x11d3 0x1447 0x1334 0x12a0 0x121b 0x11de 0x11d9 0x1447 0x1334 0x12a0 0x121b 0x11de 0x11d9 0x1447 0x1334 0x12a0 0x121b 0x11de 0x11d9>;
				};

				qcom,pc-temp-y2-lut {
					qcom,lut-col-legend = <0xfffffff6 0x00 0x0a 0x19 0x28 0x32>;
					qcom,lut-row-legend = <0x2710 0x2648 0x2580 0x24b8 0x23f0 0x2328 0x2260 0x2198 0x20d0 0x2008 0x1f40 0x1e78 0x1db0 0x1ce8 0x1c20 0x1b58 0x1a90 0x19c8 0x1900 0x1838 0x1770 0x16a8 0x15e0 0x1518 0x1450 0x1388 0x12c0 0x11f8 0x1130 0x1068 0xfa0 0xed8 0xe10 0xd48 0xc80 0xbb8 0xaf0 0xa28 0x960 0x898 0x7d0 0x708 0x640 0x578 0x4b0 0x3e8 0x384 0x320 0x2bc 0x258 0x1f4 0x190 0x12c 0xc8 0x64 0x00>;
					qcom,lut-data = <0x2b66 0x2dfc 0x2ea9 0x3212 0x331a 0x350b 0x2b9b 0x2df5 0x2f18 0x3209 0x331a 0x34f7 0x2bcf 0x2df2 0x2f60 0x31e7 0x3313 0x34c6 0x2bff 0x2df3 0x2f8a 0x31bc 0x3306 0x3483 0x2c2a 0x2df6 0x2f9d 0x3197 0x32f8 0x3438 0x2c4e 0x2dfc 0x2fa2 0x3187 0x32e9 0x33ed 0x2c69 0x2e0d 0x2f75 0x3185 0x32d4 0x338c 0x2c82 0x2e25 0x2f2e 0x3182 0x32bf 0x332b 0x2c9d 0x2e2d 0x2f2c 0x3194 0x32c4 0x330f 0x2cb9 0x2e30 0x2f75 0x31f4 0x32eb 0x3309 0x2cdf 0x2e33 0x2fb5 0x3230 0x3303 0x32f9 0x2d38 0x2e40 0x2fcb 0x31db 0x32dc 0x329f 0x2db0 0x2e5b 0x2fdd 0x3159 0x329e 0x3223 0x2df0 0x2e92 0x3008 0x3149 0x3290 0x3219 0x2e0f 0x2f1a 0x306e 0x3184 0x3298 0x327d 0x2e2f 0x2f81 0x30d5 0x31cc 0x32a5 0x32c7 0x2e64 0x2f9d 0x3130 0x320c 0x32ab 0x32cd 0x2ea2 0x2fae 0x317a 0x3253 0x32b6 0x32d0 0x2ed0 0x2fbd 0x317e 0x32b9 0x32f6 0x32fc 0x2ef6 0x2fce 0x314a 0x335a 0x33b8 0x33d6 0x2f15 0x2fe2 0x3126 0x33b3 0x3430 0x3484 0x2f33 0x300c 0x3151 0x338d 0x3426 0x349b 0x2f4d 0x304e 0x319b 0x3351 0x3417 0x348b 0x2f4a 0x307f 0x31c2 0x3341 0x3424 0x3466 0x2f04 0x30a8 0x31f7 0x3339 0x347b 0x3424 0x2eb8 0x30c6 0x321c 0x333c 0x34b4 0x3401 0x2e90 0x30df 0x3227 0x3364 0x34d3 0x3437 0x2e70 0x30f4 0x3236 0x33a2 0x3507 0x3496 0x2e5b 0x30f1 0x3248 0x33d1 0x3519 0x34d9 0x2e4d 0x30c6 0x3266 0x3404 0x34f6 0x350f 0x2e3f 0x309e 0x327c 0x3430 0x34e5 0x3529 0x2e23 0x308b 0x3281 0x3458 0x352c 0x3507 0x2df0 0x307b 0x3280 0x3478 0x358b 0x34bc 0x2db9 0x306b 0x3274 0x3477 0x356e 0x347d 0x2d82 0x3049 0x3247 0x3447 0x346e 0x3438 0x2d43 0x3034 0x3216 0x3409 0x33bb 0x33f5 0x2ce9 0x3043 0x31f3 0x33a1 0x33b4 0x33bd 0x2c6e 0x305c 0x31cf 0x3330 0x33b5 0x3388 0x2bf2 0x305c 0x31b1 0x3330 0x339c 0x3343 0x2b8b 0x3038 0x3195 0x33a4 0x3343 0x32d3 0x2aff 0x300e 0x3182 0x3401 0x330a 0x3274 0x2955 0x2ff4 0x3172 0x33c9 0x3344 0x3212 0x26f7 0x2fcf 0x3156 0x336f 0x3380 0x31ca 0x265d 0x2ef3 0x3101 0x3304 0x3376 0x3263 0x2626 0x2df1 0x3109 0x32dd 0x3305 0x3234 0x2601 0x2d5b 0x3084 0x3295 0x3240 0x30f9 0x25f9 0x2d57 0x2fd3 0x32ba 0x31ce 0x30a6 0x25ee 0x2d83 0x307e 0x32b3 0x3147 0x3035 0x25e4 0x2dff 0x30b6 0x329d 0x3186 0x30af 0x25e3 0x2d8d 0x30cf 0x3214 0x30b9 0x300f 0x25da 0x2a9b 0x3078 0x3159 0x30ba 0x2fa5 0x25d2 0x27ae 0x3052 0x3160 0x30d0 0x2fa6 0x25ca 0x2767 0x2f76 0x30b5 0x3011 0x2f64 0x25c2 0x26f0 0x2f31 0x3068 0x2fdd 0x2f34 0x25c2 0x26f0 0x2f31 0x3068 0x2fdd 0x2f34 0x25c2 0x26f0 0x2f31 0x3068 0x2fdd 0x2f34>;
				};

				qcom,pc-temp-y3-lut {
					qcom,lut-col-legend = <0xfffffff6 0x00 0x0a 0x19 0x28 0x32>;
					qcom,lut-row-legend = <0x2710 0x2648 0x2580 0x24b8 0x23f0 0x2328 0x2260 0x2198 0x20d0 0x2008 0x1f40 0x1e78 0x1db0 0x1ce8 0x1c20 0x1b58 0x1a90 0x19c8 0x1900 0x1838 0x1770 0x16a8 0x15e0 0x1518 0x1450 0x1388 0x12c0 0x11f8 0x1130 0x1068 0xfa0 0xed8 0xe10 0xd48 0xc80 0xbb8 0xaf0 0xa28 0x960 0x898 0x7d0 0x708 0x640 0x578 0x4b0 0x3e8 0x384 0x320 0x2bc 0x258 0x1f4 0x190 0x12c 0xc8 0x64 0x00>;
					qcom,lut-data = <0x341f 0x33f8 0x33e0 0x33d3 0x33d2 0x33cf 0x3421 0x33f9 0x33e2 0x33d3 0x33d2 0x33cf 0x3425 0x33fa 0x33e4 0x33d3 0x33d2 0x33d0 0x3428 0x33fa 0x33e5 0x33d3 0x33d2 0x33d1 0x342b 0x33fb 0x33e6 0x33d4 0x33d1 0x33d1 0x342c 0x33fb 0x33e6 0x33d4 0x33d1 0x33d1 0x342d 0x33fb 0x33e6 0x33d4 0x33d1 0x33d2 0x342e 0x33fb 0x33e5 0x33d5 0x33d2 0x33d2 0x342e 0x33fb 0x33e4 0x33d5 0x33d2 0x33d2 0x342e 0x33fc 0x33e5 0x33d4 0x33d2 0x33d2 0x342f 0x33fd 0x33e5 0x33d4 0x33d2 0x33d2 0x3430 0x33ff 0x33e7 0x33d5 0x33d3 0x33d2 0x3432 0x3402 0x33e9 0x33d6 0x33d3 0x33d2 0x3431 0x3402 0x33ea 0x33d7 0x33d3 0x33d2 0x342d 0x3401 0x33eb 0x33d8 0x33d3 0x33d2 0x3428 0x3400 0x33ec 0x33d8 0x33d3 0x33d2 0x3423 0x33ff 0x33eb 0x33d9 0x33d4 0x33d2 0x341f 0x33fe 0x33ea 0x33da 0x33d5 0x33d2 0x341c 0x33fd 0x33e9 0x33db 0x33d6 0x33d3 0x3419 0x33fa 0x33e7 0x33db 0x33d6 0x33d4 0x3416 0x33f7 0x33e5 0x33da 0x33d6 0x33d5 0x3413 0x33f5 0x33e2 0x33d8 0x33d4 0x33d3 0x3410 0x33f3 0x33de 0x33d6 0x33d1 0x33d1 0x340e 0x33f2 0x33dd 0x33d4 0x33d1 0x33d0 0x340e 0x33f1 0x33dd 0x33d4 0x33d1 0x33d0 0x340d 0x33f1 0x33de 0x33d3 0x33d1 0x33d0 0x340e 0x33f0 0x33df 0x33d4 0x33d1 0x33d0 0x340f 0x33ef 0x33e1 0x33d4 0x33d1 0x33d0 0x3411 0x33ef 0x33e1 0x33d4 0x33d1 0x33d0 0x3412 0x33f0 0x33e1 0x33d6 0x33d1 0x33d1 0x3413 0x33f2 0x33e0 0x33d6 0x33d1 0x33d1 0x3415 0x33f3 0x33e1 0x33d6 0x33d2 0x33d1 0x3416 0x33f4 0x33e2 0x33d7 0x33d2 0x33d1 0x3417 0x33f5 0x33e2 0x33d7 0x33d2 0x33d1 0x3418 0x33f6 0x33e3 0x33d7 0x33d2 0x33d0 0x3418 0x33f7 0x33e4 0x33d7 0x33d2 0x33d0 0x3419 0x33f9 0x33e4 0x33d6 0x33d2 0x33d1 0x341a 0x33fb 0x33e5 0x33d6 0x33d2 0x33d1 0x341a 0x33fc 0x33e5 0x33d6 0x33d2 0x33d1 0x341b 0x33fc 0x33e6 0x33d6 0x33d2 0x33d2 0x341c 0x33fd 0x33e6 0x33d6 0x33d2 0x33d3 0x3421 0x33fd 0x33e8 0x33d8 0x33d2 0x33d3 0x342c 0x33fe 0x33e9 0x33d9 0x33d3 0x33d3 0x3438 0x33fc 0x33ea 0x33d9 0x33d3 0x33d3 0x343d 0x33fb 0x33ec 0x33da 0x33d3 0x33d3 0x343d 0x33fa 0x33eb 0x33db 0x33d6 0x33d3 0x3440 0x33fb 0x33ee 0x33de 0x33d7 0x33d4 0x344d 0x33fc 0x33ee 0x33e0 0x33d7 0x33d6 0x345a 0x33fd 0x33f0 0x33e2 0x33db 0x33d8 0x3474 0x33fc 0x33ef 0x33e2 0x33da 0x33d6 0x348c 0x33f4 0x33eb 0x33e0 0x33d9 0x33d5 0x34b5 0x33f0 0x33e8 0x33df 0x33d9 0x33d6 0x3520 0x33f4 0x33e7 0x33de 0x33d9 0x33d6 0x362b 0x33fd 0x33e8 0x33de 0x33d9 0x33d7 0x362b 0x33fd 0x33e8 0x33de 0x33d9 0x33d7 0x362b 0x33fd 0x33e8 0x33de 0x33d9 0x33d7>;
				};

				qcom,pc-temp-y4-lut {
					qcom,lut-col-legend = <0xfffffff6 0x00 0x0a 0x19 0x28 0x32>;
					qcom,lut-row-legend = <0x2710 0x2648 0x2580 0x24b8 0x23f0 0x2328 0x2260 0x2198 0x20d0 0x2008 0x1f40 0x1e78 0x1db0 0x1ce8 0x1c20 0x1b58 0x1a90 0x19c8 0x1900 0x1838 0x1770 0x16a8 0x15e0 0x1518 0x1450 0x1388 0x12c0 0x11f8 0x1130 0x1068 0xfa0 0xed8 0xe10 0xd48 0xc80 0xbb8 0xaf0 0xa28 0x960 0x898 0x7d0 0x708 0x640 0x578 0x4b0 0x3e8 0x384 0x320 0x2bc 0x258 0x1f4 0x190 0x12c 0xc8 0x64 0x00>;
					qcom,lut-data = <0x410b 0x408d 0x4068 0x4033 0x4025 0x4026 0x4105 0x408d 0x4060 0x4033 0x4024 0x4024 0x4103 0x408e 0x405b 0x4033 0x4024 0x4022 0x4103 0x408f 0x4058 0x4034 0x4025 0x4021 0x4106 0x4090 0x4057 0x4034 0x4025 0x4021 0x4109 0x4091 0x4057 0x4035 0x4026 0x4021 0x410f 0x4091 0x4058 0x4036 0x4027 0x4021 0x4117 0x4091 0x405b 0x4037 0x4028 0x4022 0x411d 0x4093 0x405e 0x4038 0x4029 0x4023 0x4121 0x409b 0x4063 0x403c 0x402a 0x4024 0x4129 0x40a6 0x4068 0x403f 0x402c 0x4025 0x415b 0x40b0 0x406d 0x4042 0x402e 0x4027 0x41aa 0x40bd 0x4073 0x4045 0x4030 0x4029 0x41ba 0x40d0 0x407d 0x4049 0x4033 0x402b 0x41a6 0x40f1 0x408e 0x404e 0x4037 0x402e 0x418c 0x4107 0x40a2 0x4054 0x403b 0x4032 0x4171 0x410b 0x40bb 0x405e 0x4040 0x4036 0x4155 0x410c 0x40d2 0x4069 0x4045 0x403b 0x4141 0x4106 0x40d1 0x406f 0x404a 0x403e 0x4133 0x40e1 0x40ac 0x4071 0x4051 0x4042 0x4127 0x40ba 0x4087 0x4071 0x4055 0x4043 0x411b 0x40a0 0x406d 0x405b 0x4047 0x403a 0x410f 0x408b 0x405a 0x403a 0x4030 0x402a 0x4106 0x4088 0x4056 0x4034 0x402a 0x4026 0x40fd 0x4089 0x4055 0x4034 0x4029 0x4026 0x40f9 0x408b 0x4055 0x4035 0x4029 0x4026 0x40fd 0x408e 0x4056 0x4036 0x4029 0x4026 0x4109 0x4094 0x4059 0x4038 0x402b 0x4028 0x4119 0x4099 0x405c 0x403b 0x402e 0x4029 0x4133 0x40a0 0x4061 0x403f 0x4031 0x402c 0x4152 0x40a9 0x4068 0x4043 0x4034 0x402f 0x4173 0x40ba 0x406d 0x4048 0x403a 0x4033 0x4197 0x40d2 0x4073 0x404d 0x403f 0x4037 0x41bc 0x40eb 0x407c 0x404e 0x403e 0x4036 0x41e6 0x4107 0x408a 0x404c 0x4037 0x402f 0x4210 0x4124 0x4097 0x404a 0x4031 0x4029 0x423f 0x4144 0x40a0 0x4048 0x402e 0x4027 0x426c 0x4164 0x40a6 0x4046 0x402d 0x4025 0x427b 0x4182 0x40ae 0x4047 0x402d 0x4025 0x427c 0x419d 0x40b6 0x404c 0x4031 0x4027 0x427d 0x41b8 0x40c1 0x4051 0x4034 0x4029 0x4263 0x41d8 0x40d4 0x4056 0x4035 0x4029 0x421d 0x41f3 0x40ef 0x405a 0x4035 0x402a 0x4195 0x4201 0x410f 0x4060 0x4034 0x4028 0x411a 0x41f9 0x412c 0x406e 0x4039 0x4029 0x40e9 0x415d 0x40f9 0x4071 0x403f 0x4032 0x40e8 0x414f 0x4104 0x407a 0x4045 0x4037 0x40f7 0x4147 0x410e 0x4089 0x404e 0x4043 0x4117 0x4134 0x4118 0x409a 0x4061 0x4059 0x4125 0x4112 0x40fe 0x40a0 0x405c 0x403f 0x410e 0x40d3 0x40c5 0x4091 0x404e 0x4038 0x4101 0x40a8 0x40a3 0x4085 0x4056 0x403c 0x4113 0x409f 0x4094 0x4074 0x4056 0x4043 0x4148 0x40a2 0x408c 0x406c 0x4058 0x404e 0x4148 0x40a2 0x408c 0x406c 0x4058 0x404e 0x4148 0x40a2 0x408c 0x406c 0x4058 0x404e>;
				};

				qcom,pc-temp-y5-lut {
					qcom,lut-col-legend = <0xfffffff6 0x00 0x0a 0x19 0x28 0x32>;
					qcom,lut-row-legend = <0x2710 0x2648 0x2580 0x24b8 0x23f0 0x2328 0x2260 0x2198 0x20d0 0x2008 0x1f40 0x1e78 0x1db0 0x1ce8 0x1c20 0x1b58 0x1a90 0x19c8 0x1900 0x1838 0x1770 0x16a8 0x15e0 0x1518 0x1450 0x1388 0x12c0 0x11f8 0x1130 0x1068 0xfa0 0xed8 0xe10 0xd48 0xc80 0xbb8 0xaf0 0xa28 0x960 0x898 0x7d0 0x708 0x640 0x578 0x4b0 0x3e8 0x384 0x320 0x2bc 0x258 0x1f4 0x190 0x12c 0xc8 0x64 0x00>;
					qcom,lut-data = <0x37a8 0x4bb9 0x3cbc 0x5399 0x8181 0x4d3a 0x3b7d 0x4f8b 0x4afc 0x5069 0x7a5d 0x6203 0x418a 0x5214 0x53ea 0x4e44 0x731f 0x71af 0x4817 0x5391 0x58c3 0x4cec 0x6c50 0x7c8a 0x4d69 0x543b 0x5ac4 0x4c25 0x667e 0x82dc 0x4fc5 0x544b 0x5b28 0x4bb0 0x6236 0x84e7 0x4f8a 0x5369 0x57c6 0x4bb1 0x5f65 0x810e 0x4f08 0x51c2 0x51b7 0x4bd7 0x5d31 0x7988 0x4eb3 0x501f 0x4e72 0x4aa5 0x5b1f 0x736c 0x4d22 0x4e3b 0x4c50 0x4645 0x5953 0x6d09 0x4bf8 0x4d4b 0x4b41 0x438c 0x5734 0x66e4 0x4c4e 0x4cf2 0x4c01 0x453b 0x53d3 0x60fa 0x4d33 0x4c47 0x4d61 0x47da 0x4fe2 0x5b55 0x4f3b 0x4c1f 0x4d3a 0x482d 0x4cbb 0x5714 0x5598 0x4c69 0x4bbd 0x4736 0x49c1 0x5307 0x5a11 0x4d14 0x4ad1 0x4693 0x4859 0x500b 0x595d 0x5190 0x4bbb 0x46cb 0x4a5e 0x4db4 0x57ec 0x58ce 0x4e15 0x476d 0x4ec0 0x4bae 0x57aa 0x5c73 0x5262 0x4a5d 0x53a6 0x4e06 0x58d0 0x5eab 0x5c62 0x55e3 0x5a43 0x5d79 0x59f4 0x5fa2 0x6299 0x5d40 0x5eb8 0x691d 0x5a21 0x5f57 0x5b1f 0x5cdc 0x603a 0x6a90 0x59d0 0x5e97 0x4e9c 0x5bf5 0x6172 0x6b5b 0x59b0 0x5d91 0x4bf6 0x5a2e 0x62e6 0x6ca0 0x5a6d 0x5bc2 0x4cea 0x5513 0x6516 0x6e5c 0x5b25 0x5a1d 0x4e89 0x51db 0x6675 0x6ee1 0x5ad0 0x57be 0x53d7 0x51da 0x64fc 0x6bb2 0x59fc 0x54e7 0x5b06 0x51ef 0x61d6 0x6710 0x5993 0x54ca 0x5bf4 0x5333 0x5f31 0x64fa 0x59bf 0x574e 0x57c5 0x5948 0x5b1e 0x61d3 0x5a0a 0x5916 0x5472 0x5d45 0x58cf 0x5fba 0x5a30 0x584b 0x54f3 0x5cc4 0x5b17 0x5dc7 0x5a4a 0x56a9 0x5657 0x5bba 0x5eba 0x5adf 0x5a51 0x557a 0x5663 0x5a94 0x5f86 0x5bc0 0x5a87 0x5478 0x5587 0x5876 0x5f83 0x6377 0x5ad9 0x53f7 0x549f 0x5670 0x5f63 0x68b1 0x5b5f 0x541b 0x53df 0x54c8 0x5d5e 0x674a 0x5c39 0x5457 0x5318 0x52dc 0x594d 0x6508 0x5d48 0x544e 0x5237 0x5062 0x5514 0x6509 0x5f0e 0x53cf 0x5074 0x4c4f 0x4f79 0x67cd 0x616e 0x5377 0x4f20 0x4a02 0x4c5f 0x6a6d 0x64fd 0x53f1 0x4e34 0x4d6b 0x4d02 0x6bc4 0x690a 0x5520 0x4d65 0x510b 0x4e8a 0x6c1a 0x636b 0x57ca 0x4e8b 0x4ec8 0x5210 0x6832 0x5791 0x5b32 0x5126 0x4f63 0x528c 0x6159 0x3fec 0x6090 0x5953 0x519b 0x5690 0x53b3 0x3ca2 0x6252 0x5ba8 0x53ea 0x57a2 0x568f 0x3c29 0x627a 0x5ab2 0x57e7 0x53c1 0x628c 0x3b42 0x61ad 0x5cae 0x5b89 0x61cf 0x68fe 0x3e33 0x5e41 0x5eba 0x5ef2 0x633e 0x602a 0x3b45 0x52b6 0x6353 0x6594 0x6515 0x64b4 0x35ea 0x4508 0x6348 0x67d2 0x6db7 0x6df9 0x3443 0x42d2 0x6561 0x689d 0x6e54 0x70d5 0x32b7 0x430a 0x6447 0x6851 0x6c13 0x6be3 0x32b7 0x430a 0x6447 0x6851 0x6c13 0x6be3 0x32b7 0x430a 0x6447 0x6851 0x6c13 0x6be3>;
				};

				qcom,pc-temp-y6-lut {
					qcom,lut-col-legend = <0xfffffff6 0x00 0x0a 0x19 0x28 0x32>;
					qcom,lut-row-legend = <0x2710 0x2648 0x2580 0x24b8 0x23f0 0x2328 0x2260 0x2198 0x20d0 0x2008 0x1f40 0x1e78 0x1db0 0x1ce8 0x1c20 0x1b58 0x1a90 0x19c8 0x1900 0x1838 0x1770 0x16a8 0x15e0 0x1518 0x1450 0x1388 0x12c0 0x11f8 0x1130 0x1068 0xfa0 0xed8 0xe10 0xd48 0xc80 0xbb8 0xaf0 0xa28 0x960 0x898 0x7d0 0x708 0x640 0x578 0x4b0 0x3e8 0x384 0x320 0x2bc 0x258 0x1f4 0x190 0x12c 0xc8 0x64 0x00>;
					qcom,lut-data = <0x14b4 0x13da 0x1381 0x1349 0x133e 0x133c 0x14ad 0x13d7 0x1380 0x1349 0x133e 0x133c 0x14a5 0x13d4 0x137e 0x1349 0x133e 0x133c 0x149e 0x13d1 0x137c 0x1349 0x133e 0x133d 0x1498 0x13ce 0x137b 0x1349 0x133e 0x133d 0x1493 0x13cb 0x137a 0x1349 0x133e 0x133d 0x1490 0x13c8 0x1379 0x1349 0x133f 0x133d 0x148e 0x13c5 0x1377 0x134a 0x133f 0x133d 0x148c 0x13c5 0x1377 0x134a 0x1340 0x133e 0x148a 0x13c6 0x1378 0x134b 0x1340 0x133e 0x1489 0x13c7 0x1379 0x134b 0x1341 0x133f 0x1494 0x13ca 0x137b 0x134c 0x1341 0x133f 0x14a8 0x13cf 0x137d 0x134e 0x1342 0x1340 0x14ab 0x13d4 0x1381 0x1350 0x1343 0x1340 0x14a2 0x13db 0x1386 0x1351 0x1344 0x1341 0x1496 0x13df 0x138b 0x1354 0x1345 0x1342 0x148c 0x13e0 0x1391 0x1357 0x1347 0x1344 0x1482 0x13df 0x1397 0x135b 0x134a 0x1345 0x147b 0x13dd 0x1397 0x135d 0x134c 0x1347 0x1474 0x13d0 0x138b 0x135e 0x134e 0x1348 0x146f 0x13c3 0x137e 0x135d 0x134f 0x1349 0x146b 0x13bb 0x1375 0x1355 0x1349 0x1345 0x1468 0x13b4 0x136c 0x134a 0x1341 0x133f 0x1467 0x13b3 0x136b 0x1348 0x133f 0x133e 0x1467 0x13b3 0x136b 0x1347 0x133f 0x133d 0x1467 0x13b5 0x136c 0x1347 0x133e 0x133d 0x146b 0x13b6 0x136d 0x1348 0x133f 0x133e 0x1473 0x13b7 0x1370 0x1349 0x1340 0x133e 0x147c 0x13ba 0x1371 0x134a 0x1340 0x133f 0x1487 0x13be 0x1373 0x134c 0x1341 0x133f 0x1494 0x13c4 0x1375 0x134e 0x1342 0x1340 0x14a3 0x13cc 0x1377 0x1350 0x1344 0x1342 0x14b3 0x13d5 0x137a 0x1352 0x1346 0x1343 0x14c2 0x13df 0x137e 0x1352 0x1346 0x1343 0x14d3 0x13e9 0x1383 0x1352 0x1344 0x1341 0x14e3 0x13f5 0x1388 0x1351 0x1342 0x133f 0x14f6 0x1401 0x138c 0x1351 0x1342 0x133e 0x150a 0x140e 0x138f 0x1350 0x1341 0x133e 0x1517 0x141a 0x1392 0x1350 0x1341 0x133e 0x1521 0x1425 0x1395 0x1352 0x1342 0x1340 0x1527 0x1430 0x139a 0x1354 0x1343 0x1341 0x1527 0x143e 0x13a2 0x1357 0x1344 0x1341 0x1524 0x144b 0x13ad 0x1359 0x1344 0x1342 0x150d 0x1455 0x13b9 0x135b 0x1344 0x1341 0x14f7 0x1455 0x13c6 0x1360 0x1346 0x1342 0x14f4 0x1432 0x13b8 0x1362 0x134a 0x1344 0x14fc 0x1432 0x13be 0x1367 0x134d 0x1347 0x1511 0x1434 0x13c4 0x136e 0x134f 0x134c 0x152e 0x1434 0x13cb 0x1375 0x1358 0x1353 0x154e 0x142e 0x13c5 0x1377 0x1356 0x134a 0x1566 0x1418 0x13b4 0x1372 0x1351 0x1348 0x1597 0x1410 0x13aa 0x136f 0x1355 0x134b 0x1607 0x1418 0x13aa 0x136c 0x1355 0x134d 0x16fe 0x142d 0x13ab 0x136b 0x1357 0x1352 0x16fe 0x142d 0x13ab 0x136b 0x1357 0x1352 0x16fe 0x142d 0x13ab 0x136b 0x1357 0x1352>;
				};
			};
